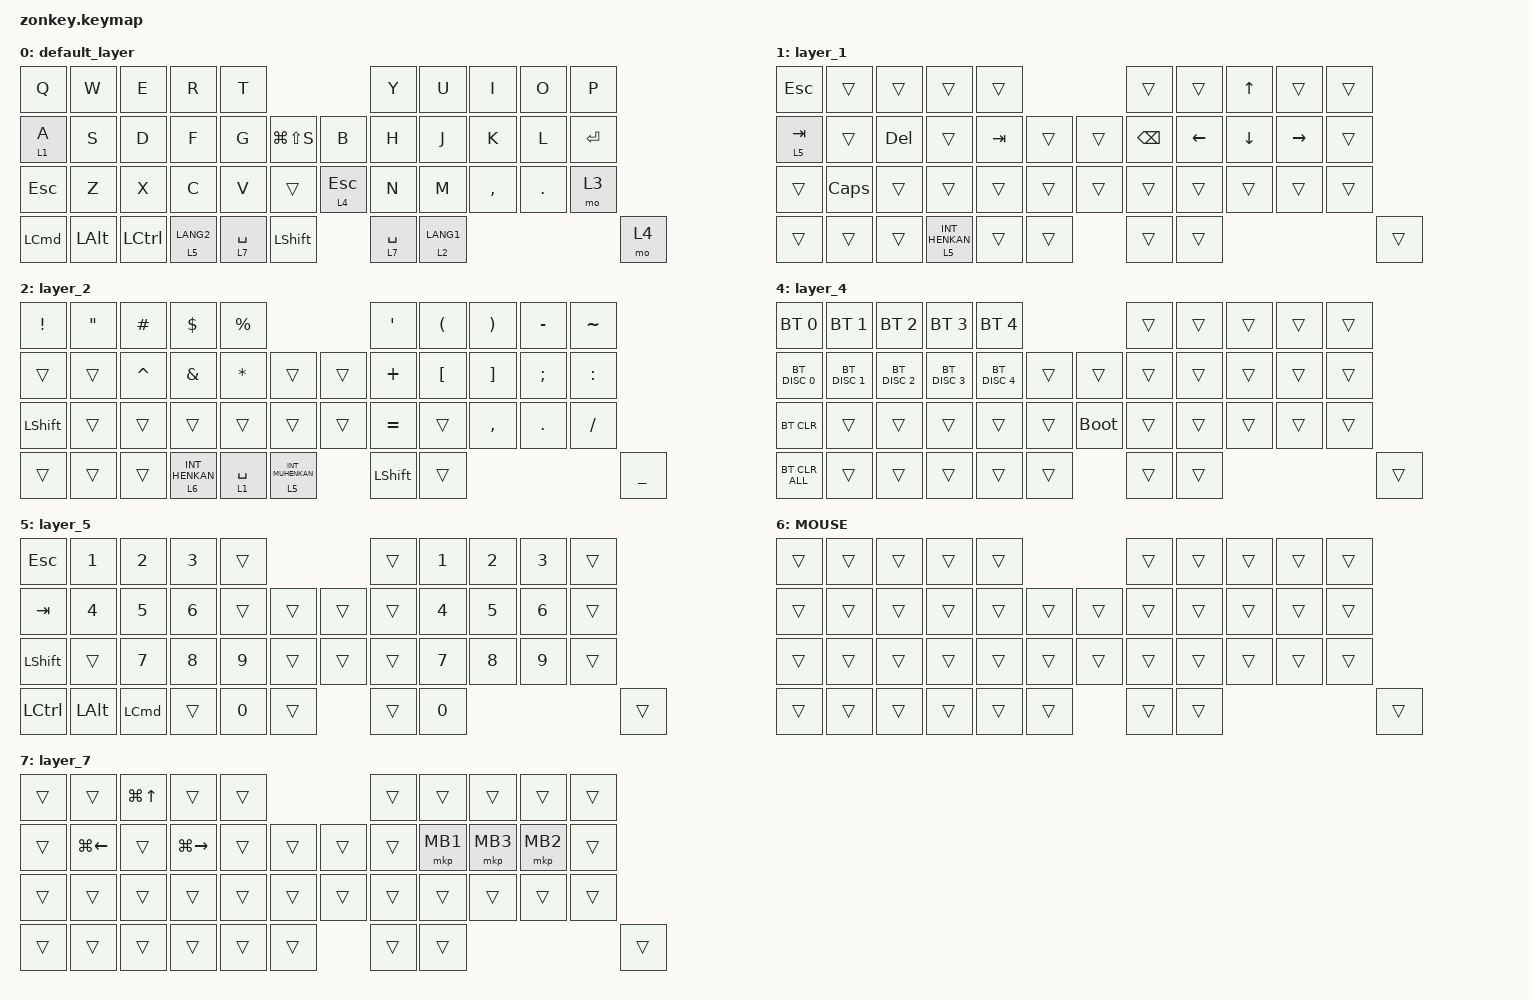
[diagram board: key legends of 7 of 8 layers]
#include <behaviors.dtsi>
#include <dt-bindings/zmk/bt.h>
#include <dt-bindings/zmk/keys.h>
#include <dt-bindings/zmk/pointing.h>

#define ZMK_POINTING_DEFAULT_SCRL_VAL 100
#define JIS 1
#define BT 4
#define MOUSE 6

&mt {
    flavor = "balanced";
    quick-tap-ms = <0>;
};

/ {
    combos { compatible = "zmk,combos"; };

    macros {
        to_layer_0: to_layer_0 {
            compatible = "zmk,behavior-macro-one-param";
            #binding-cells = <1>;
            bindings = <&to 0 &macro_param_1to1 &kp MACRO_PLACEHOLDER>;
            label = "TO_LAYER_0";
        };

        mac_screenshot: mac_screenshot {
            compatible = "zmk,behavior-macro";
            #binding-cells = <0>;
            bindings = <&kp LEFT_COMMAND &kp LEFT_SHIFT &kp NUMBER_4>;
            label = "MAC_SCREENSHOT";
        };
    };

    behaviors {
        lt_to_layer_0: lt_to_layer_0 {
            compatible = "zmk,behavior-hold-tap";
            label = "LAYER_TAP_TO_0";
            bindings = <&mo>, <&to_layer_0>;

            #binding-cells = <2>;
            tapping-term-ms = <10>;
        };

        toJIS: toJIS {
            compatible = "zmk,behavior-hold-tap";
            label = "toJIS";
            #binding-cells = <2>;
            tapping-term-ms = <200>;
            quick-tap-ms = <0>;
            bindings = <&tog>, <&kp>;
        };

        mo2: mo2 {
            compatible = "zmk,behavior-mod-morph";
            #binding-cells = <0>;
            bindings = <&kp N2>, <&kp DQT>;

            mods = <(MOD_LSFT|MOD_RSFT)>;
        };

        mo6: mo6 {
            compatible = "zmk,behavior-mod-morph";
            #binding-cells = <0>;
            bindings = <&kp N6>, <&kp AMPS>;

            mods = <(MOD_LSFT|MOD_RSFT)>;
        };

        mo7: mo7 {
            compatible = "zmk,behavior-mod-morph";
            #binding-cells = <0>;
            bindings = <&kp N7>, <&kp APOS>;

            mods = <(MOD_LSFT|MOD_RSFT)>;
        };

        mo8: mo8 {
            compatible = "zmk,behavior-mod-morph";
            #binding-cells = <0>;
            bindings = <&kp N8>, <&kp LPAR>;

            mods = <(MOD_LSFT|MOD_RSFT)>;
        };

        mo9: mo9 {
            compatible = "zmk,behavior-mod-morph";
            #binding-cells = <0>;
            bindings = <&kp N9>, <&kp RPAR>;

            mods = <(MOD_LSFT|MOD_RSFT)>;
        };

        moMINUS: moMINUS {
            compatible = "zmk,behavior-mod-morph";
            #binding-cells = <0>;
            bindings = <&kp MINUS>, <&kp EQUAL>;

            mods = <(MOD_LSFT|MOD_RSFT)>;
        };

        moCARET: moCARET {
            compatible = "zmk,behavior-mod-morph";
            #binding-cells = <0>;
            bindings = <&kp CARET>, <&kp TILDE>;

            mods = <(MOD_LSFT|MOD_RSFT)>;
        };

        moINT3: moINT3 {
            compatible = "zmk,behavior-mod-morph";
            #binding-cells = <0>;
            bindings = <&kp INT3>, <&kp PIPE>;

            mods = <(MOD_LSFT|MOD_RSFT)>;
        };

        moAT: moAT {
            compatible = "zmk,behavior-mod-morph";
            #binding-cells = <0>;
            bindings = <&kp AT>, <&kp GRAVE>;

            mods = <(MOD_LSFT|MOD_RSFT)>;
        };

        moLBKT: moLBKT {
            compatible = "zmk,behavior-mod-morph";
            #binding-cells = <0>;
            bindings = <&kp LBKT>, <&kp LS(LBRC)>;

            mods = <(MOD_LSFT|MOD_RSFT)>;
        };

        moRBKT: moRBKT {
            compatible = "zmk,behavior-mod-morph";
            #binding-cells = <0>;
            bindings = <&kp RBKT>, <&kp LS(RBRC)>;

            mods = <(MOD_LSFT|MOD_RSFT)>;
        };

        moSEMI: moSEMI {
            compatible = "zmk,behavior-mod-morph";
            #binding-cells = <0>;
            bindings = <&kp SEMI>, <&kp PLUS>;

            mods = <(MOD_LSFT|MOD_RSFT)>;
        };

        moCOLON: moCOLON {
            compatible = "zmk,behavior-mod-morph";
            #binding-cells = <0>;
            bindings = <&kp COLON>, <&kp ASTRK>;

            mods = <(MOD_LSFT|MOD_RSFT)>;
        };

        moBSLH: moBSLH {
            compatible = "zmk,behavior-mod-morph";
            #binding-cells = <0>;
            bindings = <&kp BSLH>, <&kp UNDER>;

            mods = <(MOD_LSFT|MOD_RSFT)>;
        };

        scroll_down_up: behavior_sensor_rotate_mouse_wheel_down_up {
            compatible = "zmk,behavior-sensor-rotate";
            #sensor-binding-cells = <0>;
            bindings = <&msc SCRL_DOWN>, <&msc SCRL_UP>;

            tap-ms = <20>;
        };

        mac_kakudaishukushou: mac_kakudaishukushou {
            compatible = "zmk,behavior-sensor-rotate";
            #sensor-binding-cells = <0>;
            bindings = <&kp LG(PLUS)>, <&kp LG(MINUS)>;

            tap-ms = <20>;
            label = "MAC_KAKUDAISHUKUSHOU";
        };
    };

    keymap {
        compatible = "zmk,keymap";

        default_layer {
            bindings = <
&kp Q             &kp W         &kp E             &kp R        &kp T                                        &kp Y        &kp U        &kp I      &kp O       &kp P
&lt 1 A           &kp S         &kp D             &kp F        &kp G        &kp LG(LS(S))     &kp B         &kp H        &kp J        &kp K      &kp L       &kp ENTER
&kp ESCAPE        &kp Z         &kp X             &kp C        &kp V        &trans            &lt 4 ESCAPE  &kp N        &kp M        &kp COMMA  &kp PERIOD  &mo 3
&kp LEFT_COMMAND  &kp LEFT_ALT  &kp LEFT_CONTROL  &lt 5 LANG2  &lt 7 SPACE  &kp LEFT_SHIFT                  &lt 7 SPACE  &lt 2 LANG1                                    &mo 4
            >;

            sensor-bindings =
                <&scroll_down_up>,
                <&inc_dec_kp C_VOL_DN C_VOL_UP>;
        };

        layer_1 {
            bindings = <
&kp ESCAPE    &trans    &trans      &trans            &trans                     &trans         &trans    &kp UP_ARROW  &trans     &trans
&toJIS 5 TAB  &trans    &kp DELETE  &trans            &kp TAB  &trans    &trans  &kp BACKSPACE  &kp LEFT  &kp DOWN      &kp RIGHT  &trans
&trans        &kp CAPS  &trans      &trans            &trans   &trans    &trans  &trans         &trans    &trans        &trans     &trans
&trans        &trans    &trans      &lt 5 INT_HENKAN  &trans   &trans            &trans         &trans                                     &trans
            >;

            sensor-bindings = <&scroll_down_up>;
        };

        layer_2 {
            bindings = <
&kp EXCLAMATION  &kp DOUBLE_QUOTES  &kp HASH   &kp DOLLAR        &kp PERCENT                                 &kp SQT         &kp LEFT_PARENTHESIS  &kp RIGHT_PARENTHESIS  &kp MINUS      &kp TILDE
&trans           &trans             &kp CARET  &kp AMPERSAND     &kp ASTERISK  &trans                &trans  &kp PLUS        &kp LEFT_BRACKET      &kp RIGHT_BRACKET      &kp SEMICOLON  &kp COLON
&kp LEFT_SHIFT   &trans             &trans     &trans            &trans        &trans                &trans  &kp EQUAL       &trans                &kp COMMA              &kp PERIOD     &kp SLASH
&trans           &trans             &trans     &lt 6 INT_HENKAN  &lt 1 SPACE   &lt 5 INT_MUHENKAN            &kp LEFT_SHIFT  &trans                                                                 &kp UNDERSCORE
            >;

            sensor-bindings = <&inc_dec_kp C_VOL_DN C_VOL_UP>;
        };

        layer_3 {
            bindings = <
&kp F1   &kp F2   &kp F3            &kp F4       &kp F5                                &kp F6  &kp F7  &kp F8  &kp F9  &kp F10
&kp F11  &kp F12  &trans            &trans       &trans              &trans    &trans  &trans  &trans  &trans  &trans  &trans
&trans   &trans   &trans            &trans       &trans              &trans    &trans  &trans  &trans  &trans  &trans  &trans
&trans   &trans   &lt 4 INT_HENKAN  &lt 6 SPACE  &lt 5 INT_MUHENKAN  &mo 5             &trans  &trans
            >;

            sensor-bindings = <&scroll_down_up>;
        };

        layer_4 {
            bindings = <
&bt BT_SEL 0    &bt BT_SEL 1   &bt BT_SEL 2   &bt BT_SEL 3   &bt BT_SEL 4                          &trans  &trans  &trans  &trans  &trans
&bt BT_DISC 0   &bt BT_DISC 1  &bt BT_DISC 2  &bt BT_DISC 3  &bt BT_DISC 4  &trans    &trans       &trans  &trans  &trans  &trans  &trans
&bt BT_CLR      &trans         &trans         &trans         &trans         &trans    &bootloader  &trans  &trans  &trans  &trans  &trans
&bt BT_CLR_ALL  &trans         &trans         &trans         &trans         &trans                 &trans  &trans                          &trans
            >;

            sensor-bindings = <&scroll_down_up>;
        };

        layer_5 {
            bindings = <
&kp ESCAPE        &kp NUMBER_1  &kp NUMBER_2      &kp NUMBER_3  &trans                    &trans  &kp NUMBER_1  &kp NUMBER_2  &kp NUMBER_3  &trans
&kp TAB           &kp NUMBER_4  &kp N5            &kp NUMBER_6  &trans  &trans    &trans  &trans  &kp NUMBER_4  &kp N5        &kp NUMBER_6  &trans
&kp LEFT_SHIFT    &trans        &kp N7            &kp N8        &kp N9  &trans    &trans  &trans  &kp N7        &kp N8        &kp N9        &trans
&kp LEFT_CONTROL  &kp LEFT_ALT  &kp LEFT_COMMAND  &trans        &kp N0  &trans            &trans  &kp N0                                            &trans
            >;

            sensor-bindings = <&scroll_down_up>;
        };

        MOUSE {
            bindings = <
&trans  &trans  &trans  &trans  &trans                    &trans  &trans  &trans  &trans  &trans
&trans  &trans  &trans  &trans  &trans  &trans    &trans  &trans  &trans  &trans  &trans  &trans
&trans  &trans  &trans  &trans  &trans  &trans    &trans  &trans  &trans  &trans  &trans  &trans
&trans  &trans  &trans  &trans  &trans  &trans            &trans  &trans                          &trans
            >;

            sensor-bindings = <&scroll_down_up>;
        };

        layer_7 {
            bindings = <
&trans  &trans        &kp LG(UP_ARROW)  &trans         &trans                    &trans  &trans    &trans    &trans    &trans
&trans  &kp LG(LEFT)  &trans            &kp LG(RIGHT)  &trans  &trans    &trans  &trans  &mkp MB1  &mkp MB3  &mkp MB2  &trans
&trans  &trans        &trans            &trans         &trans  &trans    &trans  &trans  &trans    &trans    &trans    &trans
&trans  &trans        &trans            &trans         &trans  &trans            &trans  &trans                                &trans
            >;
        };
    };
};
